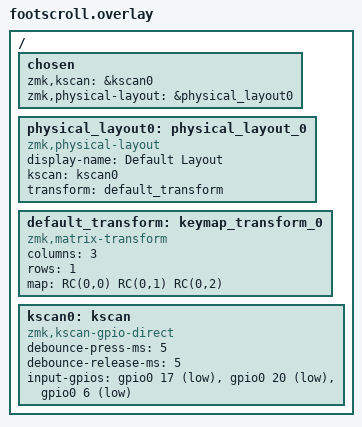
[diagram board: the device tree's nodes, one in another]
#include <dt-bindings/zmk/matrix_transform.h>

/ {
    chosen {
        zmk,kscan = &kscan0;
        zmk,physical-layout = &physical_layout0;
    };

    physical_layout0: physical_layout_0 {
        compatible = "zmk,physical-layout";
        display-name = "Default Layout";
        kscan = <&kscan0>;
        transform = <&default_transform>;
    };

    default_transform: keymap_transform_0 {
        compatible = "zmk,matrix-transform";
        columns = <3>;
        rows = <1>;
        map = <RC(0,0) RC(0,1) RC(0,2)>;
    };

kscan0: kscan {
    compatible = "zmk,kscan-gpio-direct";
    debounce-press-ms = <5>;
    debounce-release-ms = <5>;

    input-gpios
            = <&gpio0 17 (GPIO_ACTIVE_LOW | GPIO_PULL_UP)>
            , <&gpio0 20 (GPIO_ACTIVE_LOW | GPIO_PULL_UP)>
            , <&gpio0 6 (GPIO_ACTIVE_LOW | GPIO_PULL_UP)>
            ;
    };
};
